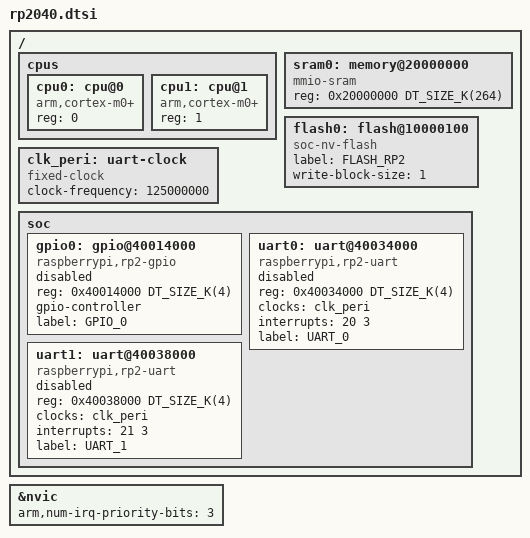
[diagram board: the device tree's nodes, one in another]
/*
 * Copyright (c) 2021 Yonatan Schachter
 *
 * SPDX-License-Identifier: Apache-2.0
 */

#include <arm/armv6-m.dtsi>
#include <dt-bindings/gpio/gpio.h>
#include <mem.h>

/ {
	cpus {
		#address-cells = <1>;
		#size-cells = <0>;

		cpu0: cpu@0 {
			compatible = "arm,cortex-m0+";
			reg = <0>;
		};

		cpu1: cpu@1 {
			compatible = "arm,cortex-m0+";
			reg = <1>;
		};
	};

	sram0: memory@20000000 {
		compatible = "mmio-sram";
		reg = <0x20000000 DT_SIZE_K(264)>;
	};

	/* Flash starts at 0x10000000 but the first 0x100 bytes
	 * are reserved for the second stage bootloader
	 */
	flash0: flash@10000100 {
		compatible = "soc-nv-flash";
		label = "FLASH_RP2";

		write-block-size = <1>;
	};

	clk_peri: uart-clock {
		compatible = "fixed-clock";
		clock-frequency = <125000000>;
		#clock-cells = <0>;
	};

	soc {
		gpio0: gpio@40014000 {
			compatible = "raspberrypi,rp2-gpio";
			reg = <0x40014000 DT_SIZE_K(4)>;
			gpio-controller;
			#gpio-cells = <2>;
			label = "GPIO_0";
			status = "disabled";
		};

		uart0: uart@40034000 {
			compatible = "raspberrypi,rp2-uart";
			reg = <0x40034000 DT_SIZE_K(4)>;
			clocks = <&clk_peri>;
			interrupts = <20 3>;
			interrupt-names = "uart0";
			label = "UART_0";
			status = "disabled";
		};

		uart1: uart@40038000 {
			compatible = "raspberrypi,rp2-uart";
			reg = <0x40038000 DT_SIZE_K(4)>;
			clocks = <&clk_peri>;
			interrupts = <21 3>;
			interrupt-names = "uart1";
			label = "UART_1";
			status = "disabled";
		};
	};
};

&nvic {
	arm,num-irq-priority-bits = <3>;
};
